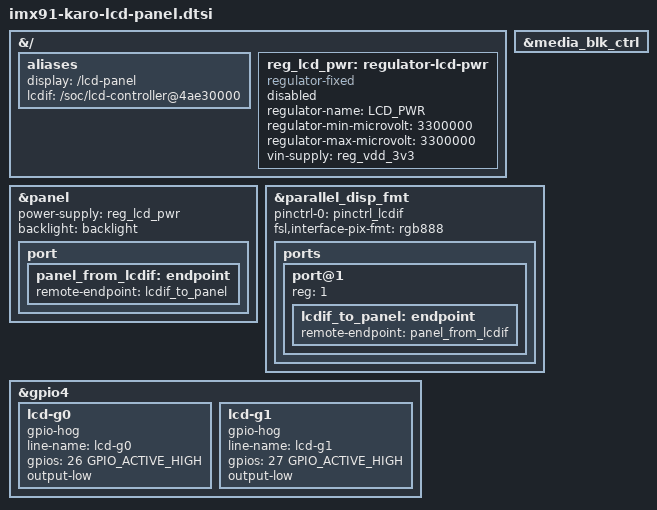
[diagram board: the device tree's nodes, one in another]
// SPDX-License-Identifier: (GPL-2.0 OR MIT)
/*
 * Copyright 2023 Lothar Waßmann <LW@KARO-electronics.de>
 *
 */

&{/} {
	aliases {
		display = "/lcd-panel";
		lcdif = "/soc/lcd-controller@4ae30000";
	};

	reg_lcd_pwr: regulator-lcd-pwr {
		compatible = "regulator-fixed";
		regulator-name = "LCD_PWR";
		regulator-min-microvolt = <3300000>;
		regulator-max-microvolt = <3300000>;
		vin-supply = <&reg_vdd_3v3>;
		status = "disabled";
	};
};

&media_blk_ctrl {
	status = "okay";
};

&panel {
	power-supply = <&reg_lcd_pwr>;
	backlight = <&backlight>;

	port {
		panel_from_lcdif: endpoint {
			remote-endpoint = <&lcdif_to_panel>;
		};
	};
};

&parallel_disp_fmt {
	pinctrl-names = "default";
	pinctrl-0 = <&pinctrl_lcdif>;
	fsl,interface-pix-fmt = "rgb888";
	status = "okay";

	ports {
		port@1 {
			reg = <1>;

			lcdif_to_panel: endpoint {
				remote-endpoint = <&panel_from_lcdif>;
			};
		};
	};
};

&gpio4 {
	lcd-g0 {
		gpio-hog;
		line-name = "lcd-g0";
		gpios = <26 GPIO_ACTIVE_HIGH>;
		output-low;
	};

	lcd-g1 {
		gpio-hog;
		line-name = "lcd-g1";
		gpios = <27 GPIO_ACTIVE_HIGH>;
		output-low;
	};
};
